# MB9BF56xR register map
File version: 2.0
CPU: CM4 r0p1, little endian, MPU, FPU, 4 interrupt priority bits
Registers are 32-bit, read-write, reset 0x0 unless marked. A register's access mark holds for its fields unless they carry their own. Offsets are from the block's base; [hi:lo] are bit positions; {n}, {i} and the like mark numbered series; 'fields as' and 'values as' point back to an identical list.

## CANPRES — CAN Prescaler Register
Base 0x40037000
0x00 CANPRE 8-bit reset 0xB — CAN Prescaler Register
  [3:0] CANPRE — CAN prescaler setting bits

## CRC — CRC Registers
Base 0x40039000
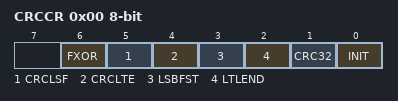
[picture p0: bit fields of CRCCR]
0x00 CRCCR 8-bit — CRC Control Register
  [6] FXOR — Initialization bit
  [5] CRCLSF — Final XOR control bit
  [4] CRCLTE — CRC result bit-order setting bit
  [3] LSBFST — CRC result byte-order setting bit
  [2] LTLEND — Bit-order setting bit
  [1] CRC32 — Byte-order setting bit
  [0] INIT — CRC mode selection bit
0x04 CRCINIT reset 0xFFFFFFFF — Initial Value Register
  [31:0] D — Initial value
0x08 CRCIN — Input Data Register
  [31:0] D — Input data
0x0C CRCR ro reset 0xFFFFFFFF — CRC Register
  [31:0] D — CRC Data

## WC — Watch Counter
Base 0x4003A000
0x00 WCRD 8-bit ro — Watch Counter Read Register
  [5:0] CTR — Counter read bits
0x01 WCRL 8-bit — Watch Counter Reload Register
  [5:0] RLC — Counter reload value setting bits
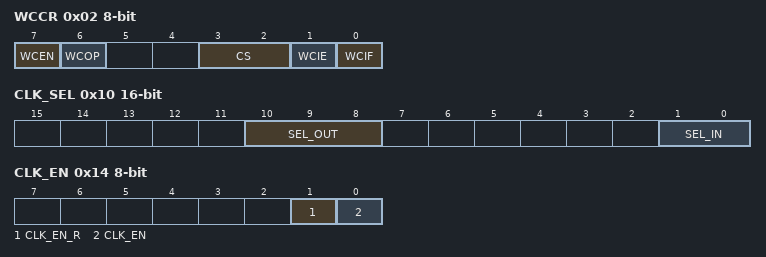
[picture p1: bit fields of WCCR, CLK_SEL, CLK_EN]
0x02 WCCR 8-bit — Watch Counter Control Register
  [7] WCEN — Watch counter operation enable bit
  [6] WCOP ro — Watch counter operating state flag
  [3:2] CS — Count clock select bits
  [1] WCIE — Interrupt request enable bit
  [0] WCIF — Interrupt request flag bit
0x10 CLK_SEL 16-bit — Clock Selection Register
  [10:8] SEL_OUT — Output clock selection bit
  [1:0] SEL_IN — Input clock selection bit
0x14 CLK_EN 8-bit — Division Clock Enable Register
  [1] CLK_EN_R — Division clock enable read bit
  [0] CLK_EN — Division clock enable bit

## LSCRP — Low-speed CR Prescaler
Base 0x4003C000
0x00 LCR_PRSLD 8-bit — Low-speed CR Prescaler Control Register
  [5:0] LCR_PRSLD — Low-speed CR Prescaler Load

## EXBUS — External Bus Interface
Base 0x4003F000
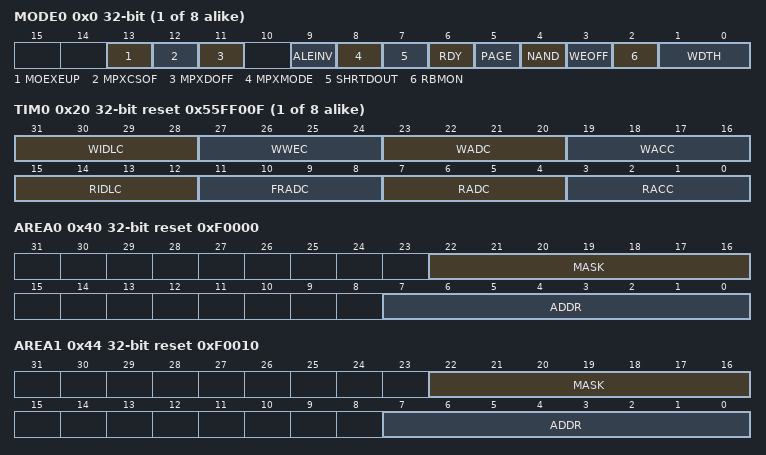
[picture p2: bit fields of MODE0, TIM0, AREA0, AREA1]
{0x0+4i} MODE{i} (i=0..7) — Mode Register {i}
  [13] MOEXEUP — select how to set the MOEX width
  [12] MPXCSOF — select a CS assertion from the start of accessing to the end of address output
  [11] MPXDOFF — select whether or not the address is output to the data lines in multiplex mode
  [9] ALEINV — set up the polarity of the ALE signal
  [8] MPXMODE — select operation bus mode
  [7] SHRTDOUT — select to which idle cycle the write data output is extended
  [6] RDY — control the external RDY function
  [5] PAGE — NOR Flash memory page access mode
  [4] NAND — NAND Flash memory mode
  [3] WEOFF — disable the write enable signal (MWEX) operation
  [2] RBMON — Read Byte Mask ON
  [1:0] WDTH — specify Data Width
{0x20+4i} TIM{i} reset 0x55FF00F (i=0..7) — Timing Register {i}
  [31:28] WIDLC — Write Idle Cycle
  [27:24] WWEC — Write Enable Cycle
  [23:20] WADC — Write Address Setup cycle
  [19:16] WACC — Write Access Cycle
  [15:12] RIDLC — Read Idle Cycle
  [11:8] FRADC — First Read Address Cycle
  [7:4] RADC — Read Address Setup cycle
  [3:0] RACC — Read Access Cycle
0x40 AREA0 reset 0xF0000 — Area Register 0
  [22:16] MASK — address mask
  [7:0] ADDR — Address
0x44 AREA1 reset 0xF0010 — Area Register 1
  [22:16] MASK — address mask
  [7:0] ADDR — Address
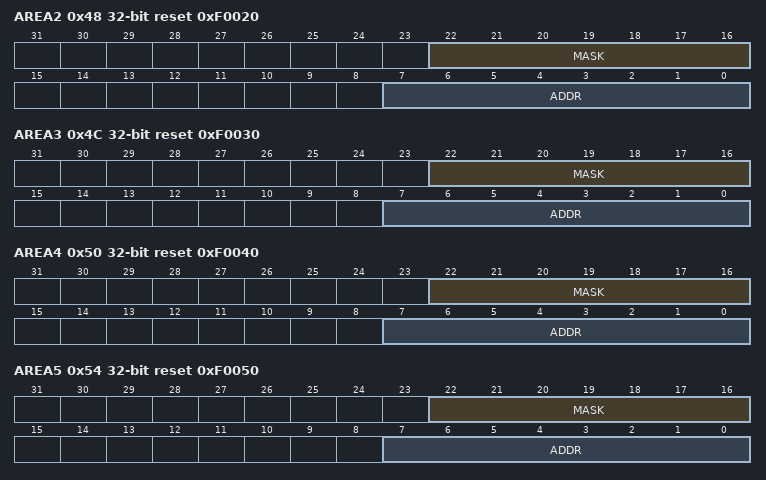
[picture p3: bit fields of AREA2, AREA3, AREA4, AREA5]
0x48 AREA2 reset 0xF0020 — Area Register 2
  [22:16] MASK — address mask
  [7:0] ADDR — Address
0x4C AREA3 reset 0xF0030 — Area Register 3
  [22:16] MASK — address mask
  [7:0] ADDR — Address
0x50 AREA4 reset 0xF0040 — Area Register 4
  [22:16] MASK — address mask
  [7:0] ADDR — Address
0x54 AREA5 reset 0xF0050 — Area Register 5
  [22:16] MASK — address mask
  [7:0] ADDR — Address
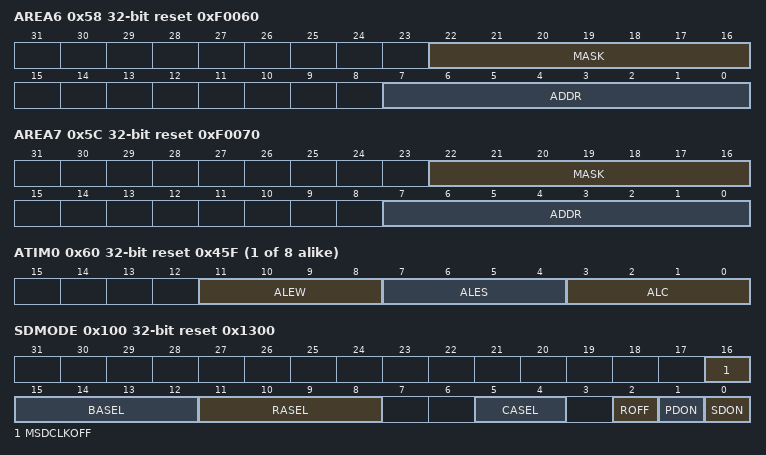
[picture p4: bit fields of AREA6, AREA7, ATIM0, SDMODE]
0x58 AREA6 reset 0xF0060 — Area Register 6
  [22:16] MASK — address mask
  [7:0] ADDR — Address
0x5C AREA7 reset 0xF0070 — Area Register 7
  [22:16] MASK — address mask
  [7:0] ADDR — Address
{0x60+4i} ATIM{i} reset 0x45F (i=0..7) — ALE Timing Register {i}
  [11:8] ALEW — Address Latch Enable Width
  [7:4] ALES — Address Latch Enable Setup cycle
  [3:0] ALC — Address Latch Cycle
0x100 SDMODE reset 0x1300 — SDRAM Mode Register
  [16] MSDCLKOFF
  [15:12] BASEL — Bank Address Select
  [11:8] RASEL — Row Address Select
  [5:4] CASEL — Column Address Select
  [2] ROFF — Refresh OFF
  [1] PDON — Power Down ON
  [0] SDON — SDRAM ON
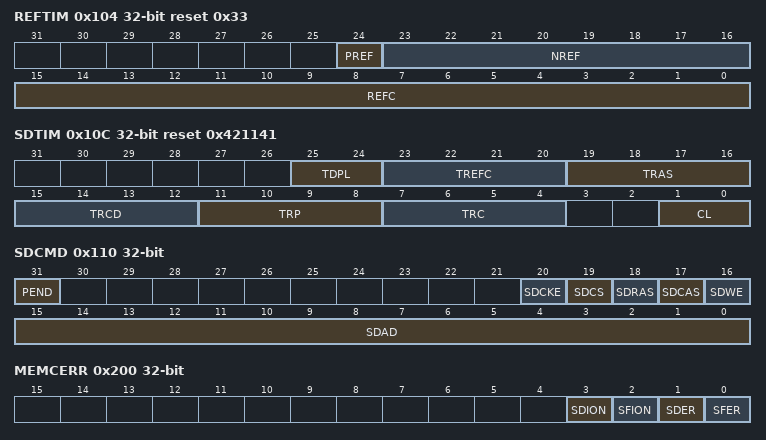
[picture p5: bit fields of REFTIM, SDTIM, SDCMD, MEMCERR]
0x104 REFTIM reset 0x33 — Refresh Timer Register
  [24] PREF — Pre-Refresh
  [23:16] NREF — Number of Refresh
  [15:0] REFC — Refresh Count
0x108 PWRDWN — Power Down Count Register
  [15:0] PDC — Power Down Count
0x10C SDTIM reset 0x421141 — SDRAM Timing Register
  [25:24] TDPL — Data-in to Precharge Lead Time
  [23:20] TREFC — Refresh Cycle time
  [19:16] TRAS — RAS active time
  [15:12] TRCD — RAS-CAS Delay
  [11:8] TRP — RAS Precharge time
  [7:4] TRC — RAS Cycle time
  [1:0] CL — CAS Latency
0x110 SDCMD — SDRAM Command Register
  [31] PEND ro
  [20] SDCKE — SDRAM CKE
  [19] SDCS — SDRAM Chip Select
  [18] SDRAS — SDRAM RAS
  [17] SDCAS — SDRAM CAS
  [16] SDWE — SDRAM Write Enable
  [15:0] SDAD — SDRAM ADress
0x200 MEMCERR — Memory Controller Register
  [3] SDION — SDRAM error Interrupt ON
  [2] SFION — SRAM/Flash error Interrupt ON
  [1] SDER — SDRAM Error
  [0] SFER — SRAM/Flash Error
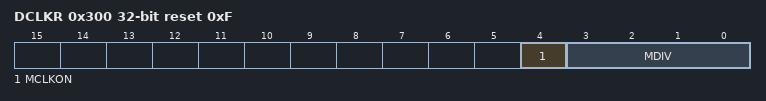
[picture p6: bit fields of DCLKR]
0x300 DCLKR reset 0xF — Division Clock Register
  [4] MCLKON
  [3:0] MDIV — MCLK Division Ratio Setup
0x304 EST ro — Error Status Register
  [0] WERR
0x308 WEAD ro — Write Error Address Register
  [31:0] ADDR
0x30C ESCLR wo reset 0x1 — Error Status Clear Register
  [0] WERRCLR — Write Error Clear
0x310 AMODE reset 0x1 — Access Mode Register
  [0] WAEN

## DMAC — DMAC Registers
Base 0x40060000
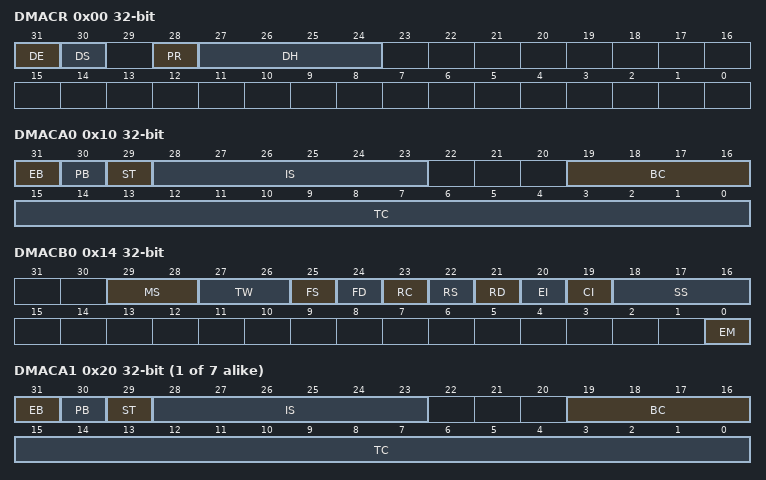
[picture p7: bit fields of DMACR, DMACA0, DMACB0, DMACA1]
0x00 DMACR — Entire DMAC Configuration Register
  [31] DE — DMA Enable (all-channel operation enable bit)
  [30] DS — DMA Stop
  [28] PR — Priority Rotation
  [27:24] DH — DMA Halt (All-channel pause bit)
0x10 DMACA0 — Configuration A Register
  [31] EB — Enable bit (individual-channel operation enable bit)
  [30] PB — Pause bit (individual-channel pause bit)
  [29] ST — Software Trigger
  [28:23] IS — Input Select
  [19:16] BC — Block Count
  [15:0] TC — Transfer Count
0x14 DMACB0 — Configuration B Register
  [29:28] MS — Mode Select
  [27:26] TW — Transfer Width
  [25] FS — Fixed Source
  [24] FD — Fixed Destination
  [23] RC — Reload Count (BC/TC reload)
  [22] RS — Reload Source
  [21] RD — Reload Destination
  [20] EI — Error Interrupt (unsuccessful transfer completion interrupt enable)
  [19] CI — Completion Interrupt (successful transfer completion interrupt enable)
  [18:16] SS — Stop Status (stop status notification)
  [0] EM — Enable bit Mask (EB bit clear mask)
0x18 DMACSA0 — Transfer Source Address Register
0x1C DMACDA0 — Transfer Destination Address Register
{0x10+0x10*i} DMACA{i} (i=1..7) — Configuration A Register {i}
  fields as DMACA0
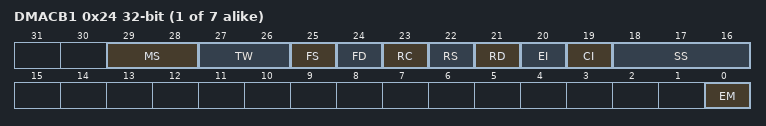
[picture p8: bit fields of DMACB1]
{0x14+0x10*i} DMACB{i} (i=1..7) — Configuration B Register {i}
  fields as DMACB0
{0x18+0x10*i} DMACSA{i} (i=1..7) — Transfer Source Address Register {i}
{0x1C+0x10*i} DMACDA{i} (i=1..7) — Transfer Destination Address Register {i}

## DSTC — DSTC registers
Base 0x40061000
0x00 DESTP — Descriptor top address Register
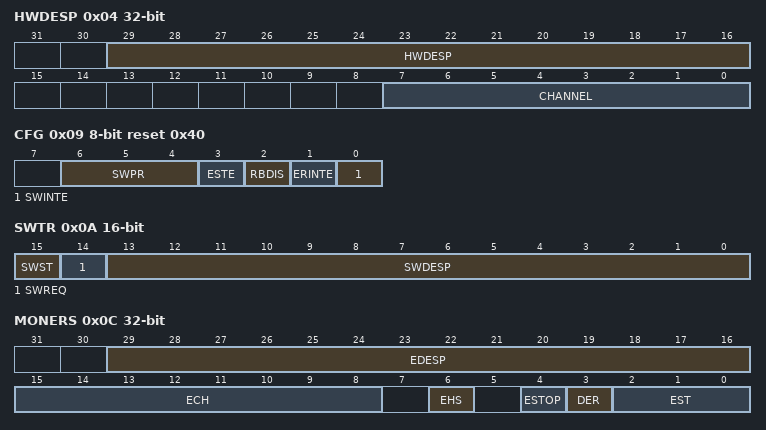
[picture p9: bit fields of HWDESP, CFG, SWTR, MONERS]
0x04 HWDESP — Hardware DES pointer Register
  [29:16] HWDESP, [7:0] CHANNEL
0x08 CMD 8-bit reset 0x1 — Command Register
0x09 CFG 8-bit reset 0x40 — Configuration Register
  [6:4] SWPR — Software transfer priority
  [3] ESTE — Error stop enable
  [2] RBDIS — Read skip buffer disable
  [1] ERINTE — Error interrupt enable
  [0] SWINTE — Software interrupt enable
0x0A SWTR 16-bit — Software trigger Register
  [15] SWST ro — Software status
  [14] SWREQ ro — Software request
  [13:0] SWDESP — Software DES pointer
0x0C MONERS ro — Transfer Error Status Monitor Register
  [29:16] EDESP — Error DES pointer
  [15:8] ECH — Error hardware channel
  [6] EHS — Error hardware software
  [4] ESTOP — Error stop
  [3] DER — Double error
  [2:0] EST — Error status
{0x10+4i} DREQENB{i} (i=0..7) — DMA request enable Register {i}
{0x30+4i} HWINT{i} ro (i=0..7) — Hardware transfer interrupt Register {i}
{0x50+4i} HWINTCLR{i} wo (i=0..7) — Hardware transfer interrupt clear Register {i}
{0x70+4i} DQMSK{i} ro (i=0..7) — DMA request mask Register {i}
{0x90+4i} DQMSKCLR{i} wo (i=0..7) — DMA request mask clear Register {i}

## WORKFLASH_IF — WorkFlash Memory
Base 0x200E0000
0x00 WFASZR reset 0x1 — WorkFlash Access Size Register
  [0] ASZ — WorkFlash Access Size
0x04 WFRWTR reset 0x4 — WorkFlash Read Wait Register
  [2:0] RWT — Read Wait Cycle
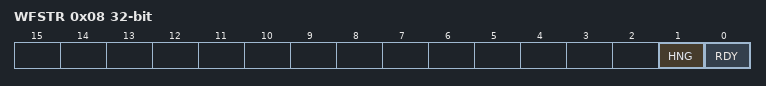
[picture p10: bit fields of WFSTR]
0x08 WFSTR ro — WorkFlash Status Register
  [1] HNG — WorkFlash Hang
  [0] RDY — WorkFlash Rdy

## Notices in the file
Copyright (C) 2015 Spansion LLC. All Rights Reserved.
This software is owned and published by:
Spansion LLC, 915 DeGuigne Dr. Sunnyvale, CA  94088-3453 ("Spansion").
BY DOWNLOADING, INSTALLING OR USING THIS SOFTWARE, YOU AGREE TO BE BOUND
BY ALL THE TERMS AND CONDITIONS OF THIS AGREEMENT.
This software contains source code for use with Spansion
components. This software is licensed by Spansion to be adapted only
for use in systems utilizing Spansion components. Spansion shall not be
responsible for misuse or illegal use of this software for devices not
supported herein.  Spansion is providing this software "AS IS" and will
not be responsible for issues arising from incorrect user implementation
of the software.
SPANSION MAKES NO WARRANTY, EXPRESS OR IMPLIED, ARISING BY LAW OR OTHERWISE,
REGARDING THE SOFTWARE (INCLUDING ANY ACOOMPANYING WRITTEN MATERIALS),
ITS PERFORMANCE OR SUITABILITY FOR YOUR INTENDED USE, INCLUDING,
WITHOUT LIMITATION, THE IMPLIED WARRANTY OF MERCHANTABILITY, THE IMPLIED
WARRANTY OF FITNESS FOR A PARTICULAR PURPOSE OR USE, AND THE IMPLIED
WARRANTY OF NONINFRINGEMENT.
SPANSION SHALL HAVE NO LIABILITY (WHETHER IN CONTRACT, WARRANTY, TORT,
NEGLIGENCE OR OTHERWISE) FOR ANY DAMAGES WHATSOEVER (INCLUDING, WITHOUT
LIMITATION, DAMAGES FOR LOSS OF BUSINESS PROFITS, BUSINESS INTERRUPTION,
LOSS OF BUSINESS INFORMATION, OR OTHER PECUNIARY LOSS) ARISING FROM USE OR
INABILITY TO USE THE SOFTWARE, INCLUDING, WITHOUT LIMITATION, ANY DIRECT,
INDIRECT, INCIDENTAL, SPECIAL OR CONSEQUENTIAL DAMAGES OR LOSS OF DATA,
SAVINGS OR PROFITS,
EVEN IF SPANSION HAS BEEN ADVISED OF THE POSSIBILITY OF SUCH DAMAGES.
YOU ASSUME ALL RESPONSIBILITIES FOR SELECTION OF THE SOFTWARE TO ACHIEVE YOUR
INTENDED RESULTS, AND FOR THE INSTALLATION OF, USE OF, AND RESULTS OBTAINED
FROM, THE SOFTWARE.
This software may be replicated in part or whole for the licensed use,
with the restriction that this Disclaimer and Copyright notice must be
included with each copy of this software, whether used in part or whole,
at all times.
